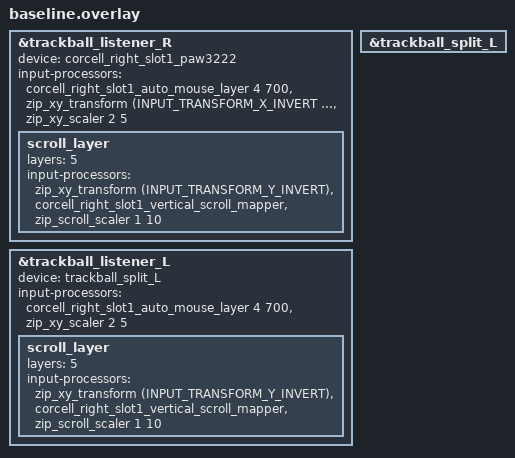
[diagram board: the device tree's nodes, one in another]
/* Diagnostic only: use the main branch pointer pipeline, bypassing Studio runtime settings. */
#include <dt-bindings/zmk/input_transform.h>
#include <input/processors.dtsi>

&trackball_listener_R {
    status = "okay";
    device = <&corcell_right_slot1_paw3222>;
    input-processors =
        <&corcell_right_slot1_auto_mouse_layer 4 700>,
        <&zip_xy_transform (INPUT_TRANSFORM_X_INVERT | INPUT_TRANSFORM_Y_INVERT)>,
        <&zip_xy_scaler 2 5>;

    scroll_layer {
        layers = <5>;
        input-processors =
            <&zip_xy_transform (INPUT_TRANSFORM_Y_INVERT)>,
            <&corcell_right_slot1_vertical_scroll_mapper>,
            <&zip_scroll_scaler 1 10>;
    };
};

/* Input relayed from the left half. */
&trackball_split_L {
    status = "okay";
};

&trackball_listener_L {
    status = "okay";
    device = <&trackball_split_L>;
    /*
     * The left FPC slot is the mirror image of the right one, so the same
     * module sits rotated 180 degrees and needs no inversion.
     */
    input-processors =
        <&corcell_right_slot1_auto_mouse_layer 4 700>,
        <&zip_xy_scaler 2 5>;

    scroll_layer {
        layers = <5>;
        input-processors =
            <&zip_xy_transform (INPUT_TRANSFORM_Y_INVERT)>,
            <&corcell_right_slot1_vertical_scroll_mapper>,
            <&zip_scroll_scaler 1 10>;
    };
};

